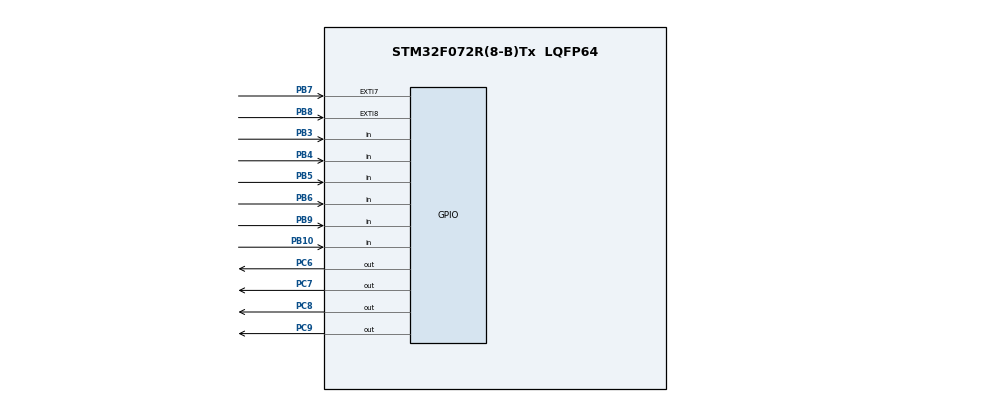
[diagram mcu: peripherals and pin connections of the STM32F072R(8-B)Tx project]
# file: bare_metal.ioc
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Mcu.Family=STM32F0
Mcu.Name=STM32F072R(8-B)Tx
Mcu.Package=LQFP64
PB10.Signal=GPIO_Input
PB3.Signal=GPIO_Input
PB4.Signal=GPIO_Input
PB5.Signal=GPIO_Input
PB6.Signal=GPIO_Input
PB7.Signal=GPXTI7
PB8.Signal=GPXTI8
PB9.Signal=GPIO_Input
PC6.Signal=GPIO_Output
PC7.Signal=GPIO_Output
PC8.Signal=GPIO_Output
PC9.Signal=GPIO_Output
ProjectManager.HeapSize=0x200
ProjectManager.StackSize=0x400
ProjectManager.TargetToolchain=STM32CubeIDE
board=custom

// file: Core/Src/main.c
/* USER CODE BEGIN Header */
/**
  ******************************************************************************
  * @file           : main.c
  * @brief          : Main program body
  ******************************************************************************
  * @attention
  *
  * Copyright (c) 2023 STMicroelectronics.
  * All rights reserved.
  *
  * This software is licensed under terms that can be found in the LICENSE file
  * in the root directory of this software component.
  * If no LICENSE file comes with this software, it is provided AS-IS.
  *
  ******************************************************************************
  */
/* USER CODE END Header */
#include "main.h"

/* USER CODE BEGIN Includes */
#include "custom_gpio_mnemonics.h"
#include "custom_gpio.h"
#include "custom_rcc_mnemonics.h"
/* USER CODE END Includes */

void SystemClock_Config(void);
static void MX_GPIO_Init(void);

/* USER CODE BEGIN 0 */
uint16_t port_val;
/* USER CODE END 0 */

int main(void)
{

  /* MCU Configuration--------------------------------------------------------*/

  /* Reset of all peripherals, Initializes the Flash interface and the Systick. */
 // HAL_Init();

  /* Configure the system clock */
  //SystemClock_Config();

  /* Initialize all configured peripherals */
  //MX_GPIO_Init();
  /* USER CODE BEGIN 2 */
	RCC_CR2 |= (1<<16);
	while((RCC_CR2&(131072)) != 131072);
	RCC_CFGR |= 3;
	while((RCC_CFGR&12) != 12);
	RCC_AHBENR |= (1 << 17) | (1 << 19);

	GPIOA_OSPEEDR = 1;

	GPIOC_MODER = (1 << 12);

  /* USER CODE END 2 */

  /* Infinite loop */
  while (1)
  {

    /* USER CODE BEGIN 3 */
/*	  port_val = ((GPIOB->IDR) >> 3)&0xff;
	  uint8_t temp=0;
	  if(!(port_val&0x1)) temp = 1;
	  else if(!(port_val&0x2)) temp = 2;
	  else if(!(port_val&0x04)) temp = 3;
	  else if(!(port_val&0x08)) temp = 4;
	  else if(!(port_val&0x10)) temp = 5;
	  else if(!(port_val&0x20)) temp = 6;
	  else if(!(port_val&0x40)) temp = 7;
	  else if(!(port_val&0x80)) temp = 8;
	  else temp = 0;
	  GPIOC->ODR = temp<<6;*/

  }
  /* USER CODE END 3 */
}

void SystemClock_Config(void)
{
  RCC_OscInitTypeDef RCC_OscInitStruct = {0};
  RCC_ClkInitTypeDef RCC_ClkInitStruct = {0};

  /** Initializes the RCC Oscillators according to the specified parameters
  * in the RCC_OscInitTypeDef structure.
  */
  RCC_OscInitStruct.OscillatorType = RCC_OSCILLATORTYPE_HSI;
  RCC_OscInitStruct.HSIState = RCC_HSI_ON;
  RCC_OscInitStruct.HSICalibrationValue = RCC_HSICALIBRATION_DEFAULT;
  RCC_OscInitStruct.PLL.PLLState = RCC_PLL_NONE;
  if (HAL_RCC_OscConfig(&RCC_OscInitStruct) != HAL_OK)
  {
    Error_Handler();
  }

  /** Initializes the CPU, AHB and APB buses clocks
  */
  RCC_ClkInitStruct.ClockType = RCC_CLOCKTYPE_HCLK|RCC_CLOCKTYPE_SYSCLK
                              |RCC_CLOCKTYPE_PCLK1;
  RCC_ClkInitStruct.SYSCLKSource = RCC_SYSCLKSOURCE_HSI;
  RCC_ClkInitStruct.AHBCLKDivider = RCC_SYSCLK_DIV1;
  RCC_ClkInitStruct.APB1CLKDivider = RCC_HCLK_DIV1;

  if (HAL_RCC_ClockConfig(&RCC_ClkInitStruct, FLASH_LATENCY_0) != HAL_OK)
  {
    Error_Handler();
  }
}

static void MX_GPIO_Init(void)
{
  GPIO_InitTypeDef GPIO_InitStruct = {0};

  /* GPIO Ports Clock Enable */
  __HAL_RCC_GPIOB_CLK_ENABLE();
  __HAL_RCC_GPIOC_CLK_ENABLE();

  /*Configure GPIO pin Output Level */
  HAL_GPIO_WritePin(GPIOC, GPIO_PIN_6|GPIO_PIN_7|GPIO_PIN_8|GPIO_PIN_9, GPIO_PIN_RESET);

  /*Configure GPIO pins : PB10 PB3 PB4 PB5
                           PB6 PB9 */
  GPIO_InitStruct.Pin = GPIO_PIN_10|GPIO_PIN_3|GPIO_PIN_4|GPIO_PIN_5
                          |GPIO_PIN_6|GPIO_PIN_9;
  GPIO_InitStruct.Mode = GPIO_MODE_INPUT;
  GPIO_InitStruct.Pull = GPIO_NOPULL;
  HAL_GPIO_Init(GPIOB, &GPIO_InitStruct);

  /*Configure GPIO pins : PC6 PC7 PC8 PC9 */
  GPIO_InitStruct.Pin = GPIO_PIN_6|GPIO_PIN_7|GPIO_PIN_8|GPIO_PIN_9;
  GPIO_InitStruct.Mode = GPIO_MODE_OUTPUT_PP;
  GPIO_InitStruct.Pull = GPIO_NOPULL;
  GPIO_InitStruct.Speed = GPIO_SPEED_FREQ_LOW;
  HAL_GPIO_Init(GPIOC, &GPIO_InitStruct);

  /*Configure GPIO pins : PB7 PB8 */
  GPIO_InitStruct.Pin = GPIO_PIN_7|GPIO_PIN_8;
  GPIO_InitStruct.Mode = GPIO_MODE_IT_RISING;
  GPIO_InitStruct.Pull = GPIO_NOPULL;
  HAL_GPIO_Init(GPIOB, &GPIO_InitStruct);

}

void Error_Handler(void)
{
  __disable_irq();
  while (1)
  {
  }
}
